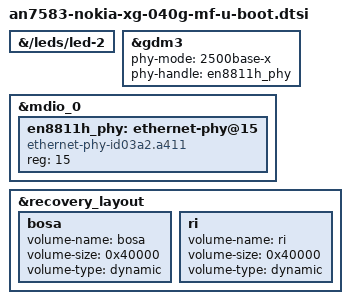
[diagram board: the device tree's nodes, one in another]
// SPDX-License-Identifier: (GPL-2.0-only OR BSD-2-Clause)

#include "an758x-recovery-layout-u-boot.dtsi"

status_led: &{/leds/led-2} {
};

#include "an758x-status-led-u-boot.dtsi"

&gdm3 {
	status = "okay";
	bootph-all;
	phy-mode = "2500base-x";
	phy-handle = <&en8811h_phy>;
};

&mdio_0 {
	#address-cells = <1>;
	#size-cells = <0>;

	en8811h_phy: ethernet-phy@15 {
		compatible = "ethernet-phy-id03a2.a411";
		reg = <15>;
	};
};

&recovery_layout {
	bosa {
		volume-name = "bosa";
		volume-size = <0x40000>;
		volume-type = "dynamic";
		bootph-all;
	};

	ri {
		volume-name = "ri";
		volume-size = <0x40000>;
		volume-type = "dynamic";
		bootph-all;
	};
};
